VERSION ""

NS_ :

BS_:

BU_: PWM_NODE COMMANDER LISTENER REQUESTER

BO_ 32 state: 2 PWM_NODE
 SG_ system_state : 0|8@1+ (1,0) [0|255] ""  LISTENER
 SG_ mcu_temperature : 8|8@1+ (1,-40) [-40|215] "degC"  LISTENER

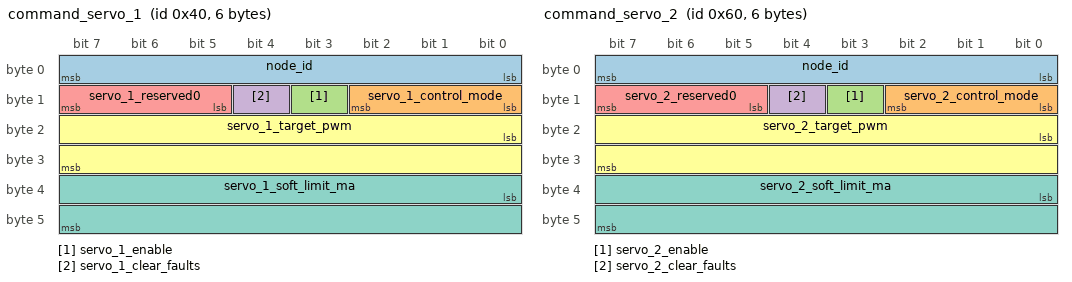
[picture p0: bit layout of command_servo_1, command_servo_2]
BO_ 64 command_servo_1: 6 COMMANDER
 SG_ node_id : 0|8@1+ (1,0) [0|255] ""  PWM_NODE
 SG_ servo_1_control_mode : 8|3@1+ (1,0) [0|7] ""  PWM_NODE
 SG_ servo_1_enable : 11|1@1+ (1,0) [0|1] ""  PWM_NODE
 SG_ servo_1_clear_faults : 12|1@1+ (1,0) [0|1] ""  PWM_NODE
 SG_ servo_1_reserved0 : 13|3@1+ (1,0) [0|7] ""  PWM_NODE
 SG_ servo_1_target_pwm : 16|16@1+ (1,0) [0|3000] "us"  PWM_NODE
 SG_ servo_1_soft_limit_ma : 32|16@1+ (1,0) [0|65535] "mA"  PWM_NODE

BO_ 96 command_servo_2: 6 COMMANDER
 SG_ node_id : 0|8@1+ (1,0) [0|255] ""  PWM_NODE
 SG_ servo_2_control_mode : 8|3@1+ (1,0) [0|7] ""  PWM_NODE
 SG_ servo_2_enable : 11|1@1+ (1,0) [0|1] ""  PWM_NODE
 SG_ servo_2_clear_faults : 12|1@1+ (1,0) [0|1] ""  PWM_NODE
 SG_ servo_2_reserved0 : 13|3@1+ (1,0) [0|7] ""  PWM_NODE
 SG_ servo_2_target_pwm : 16|16@1+ (1,0) [0|3000] "us"  PWM_NODE
 SG_ servo_2_soft_limit_ma : 32|16@1+ (1,0) [0|65535] "mA"  PWM_NODE

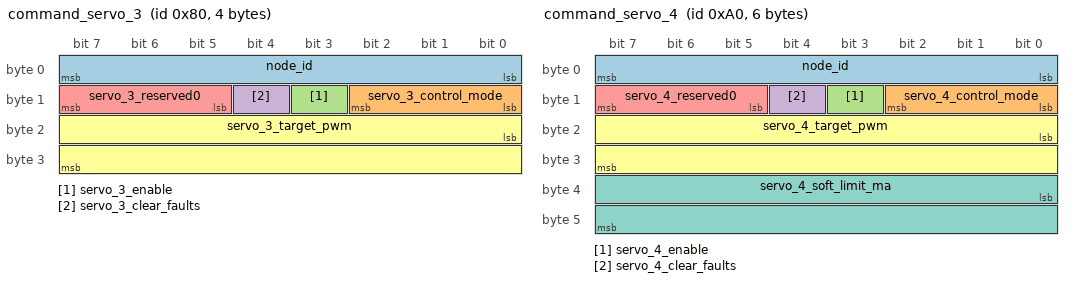
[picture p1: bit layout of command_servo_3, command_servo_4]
BO_ 128 command_servo_3: 4 COMMANDER
 SG_ node_id : 0|8@1+ (1,0) [0|255] ""  PWM_NODE
 SG_ servo_3_control_mode : 8|3@1+ (1,0) [0|7] ""  PWM_NODE
 SG_ servo_3_enable : 11|1@1+ (1,0) [0|1] ""  PWM_NODE
 SG_ servo_3_clear_faults : 12|1@1+ (1,0) [0|1] ""  PWM_NODE
 SG_ servo_3_reserved0 : 13|3@1+ (1,0) [0|7] ""  PWM_NODE
 SG_ servo_3_target_pwm : 16|16@1+ (1,0) [0|3000] "us"  PWM_NODE

BO_ 160 command_servo_4: 6 COMMANDER
 SG_ node_id : 0|8@1+ (1,0) [0|255] ""  PWM_NODE
 SG_ servo_4_control_mode : 8|3@1+ (1,0) [0|7] ""  PWM_NODE
 SG_ servo_4_enable : 11|1@1+ (1,0) [0|1] ""  PWM_NODE
 SG_ servo_4_clear_faults : 12|1@1+ (1,0) [0|1] ""  PWM_NODE
 SG_ servo_4_reserved0 : 13|3@1+ (1,0) [0|7] ""  PWM_NODE
 SG_ servo_4_target_pwm : 16|16@1+ (1,0) [0|3000] "us"  PWM_NODE
 SG_ servo_4_soft_limit_ma : 32|16@1+ (1,0) [0|65535] "mA"  PWM_NODE

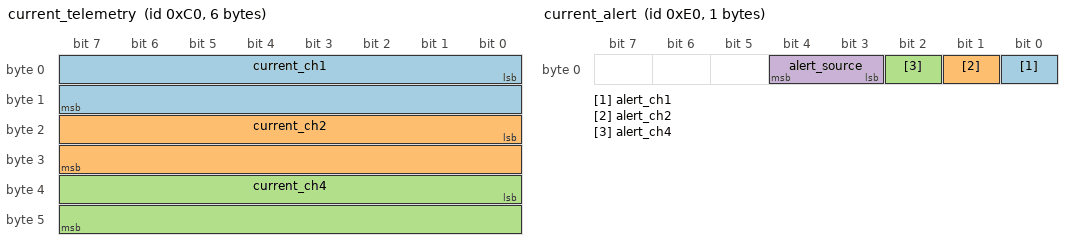
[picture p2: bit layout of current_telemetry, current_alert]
BO_ 192 current_telemetry: 6 PWM_NODE
 SG_ current_ch1 : 0|16@1+ (1,0) [0|65535] "mA"  LISTENER
 SG_ current_ch2 : 16|16@1+ (1,0) [0|65535] "mA"  LISTENER
 SG_ current_ch4 : 32|16@1+ (1,0) [0|65535] "mA"  LISTENER

BO_ 224 current_alert: 1 PWM_NODE
 SG_ alert_ch1 : 0|1@1+ (1,0) [0|1] ""  LISTENER
 SG_ alert_ch2 : 1|1@1+ (1,0) [0|1] ""  LISTENER
 SG_ alert_ch4 : 2|1@1+ (1,0) [0|1] ""  LISTENER
 SG_ alert_source : 3|2@1+ (1,0) [0|2] ""  LISTENER

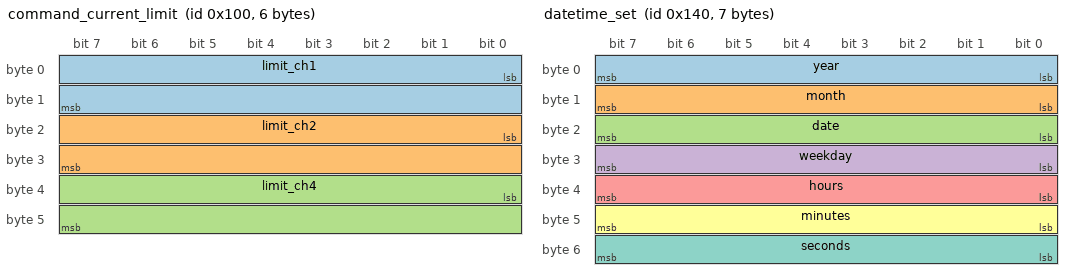
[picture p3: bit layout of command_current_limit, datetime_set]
BO_ 256 command_current_limit: 6 COMMANDER
 SG_ limit_ch1 : 0|16@1+ (1,0) [0|65535] "mA"  PWM_NODE
 SG_ limit_ch2 : 16|16@1+ (1,0) [0|65535] "mA"  PWM_NODE
 SG_ limit_ch4 : 32|16@1+ (1,0) [0|65535] "mA"  PWM_NODE

BO_ 288 command_lockout_duration: 2 COMMANDER
 SG_ lockout_duration : 0|16@1+ (1,0) [0|65535] "ms"  PWM_NODE

BO_ 320 datetime_set: 7 COMMANDER
 SG_ year : 0|8@1+ (1,0) [0|99] "year"  PWM_NODE
 SG_ month : 8|8@1+ (1,0) [1|12] "month"  PWM_NODE
 SG_ date : 16|8@1+ (1,0) [1|31] "day"  PWM_NODE
 SG_ weekday : 24|8@1+ (1,0) [1|7] "weekday"  PWM_NODE
 SG_ hours : 32|8@1+ (1,0) [0|23] "hour"  PWM_NODE
 SG_ minutes : 40|8@1+ (1,0) [0|59] "min"  PWM_NODE
 SG_ seconds : 48|8@1+ (1,0) [0|59] "sec"  PWM_NODE

BO_ 352 datetime_get: 0 REQUESTER

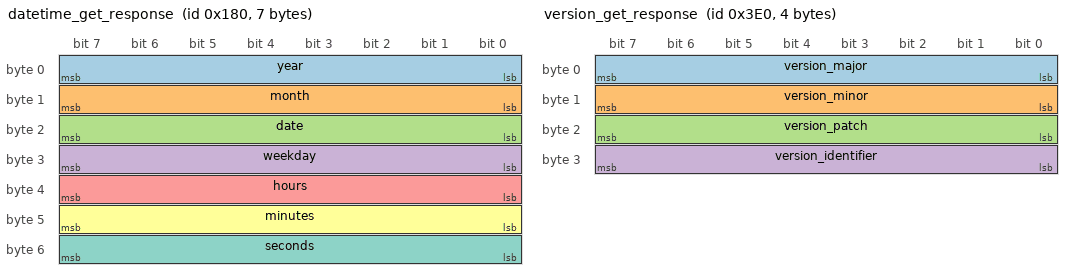
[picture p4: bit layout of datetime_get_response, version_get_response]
BO_ 384 datetime_get_response: 7 PWM_NODE
 SG_ year : 0|8@1+ (1,0) [0|99] "year"  REQUESTER
 SG_ month : 8|8@1+ (1,0) [1|12] "month"  REQUESTER
 SG_ date : 16|8@1+ (1,0) [1|31] "day"  REQUESTER
 SG_ weekday : 24|8@1+ (1,0) [1|7] "weekday"  REQUESTER
 SG_ hours : 32|8@1+ (1,0) [0|23] "hour"  REQUESTER
 SG_ minutes : 40|8@1+ (1,0) [0|59] "min"  REQUESTER
 SG_ seconds : 48|8@1+ (1,0) [0|59] "sec"  REQUESTER

BO_ 960 version_get: 0 REQUESTER

BO_ 992 version_get_response: 4 PWM_NODE
 SG_ version_major : 0|8@1+ (1,0) [0|255] "major"  REQUESTER
 SG_ version_minor : 8|8@1+ (1,0) [0|255] "minor"  REQUESTER
 SG_ version_patch : 16|8@1+ (1,0) [0|255] "patch"  REQUESTER
 SG_ version_identifier : 24|8@1+ (1,0) [0|255] "ascii"  REQUESTER

BA_DEF_  "BusType" STRING ;
BA_DEF_DEF_  "BusType" "CAN";
